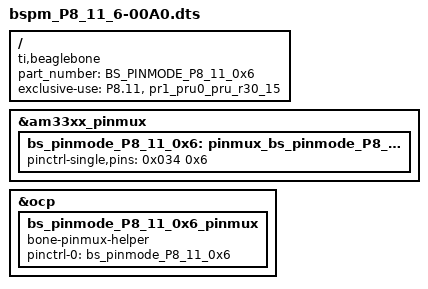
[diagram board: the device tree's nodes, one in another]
/*
 * This is a template-generated file from BoneScript
 */

/dts-v1/;
/plugin/;

/{
    compatible = "ti,beaglebone", "ti,beaglebone-black", "ti,beaglebone-green";
    part_number = "BS_PINMODE_P8_11_0x6";

    exclusive-use =
        "P8.11",
        "pr1_pru0_pru_r30_15";

    fragment@0 {
        target = <&am33xx_pinmux>;
        __overlay__ {
            bs_pinmode_P8_11_0x6: pinmux_bs_pinmode_P8_11_0x6 {
                pinctrl-single,pins = <0x034 0x6>;
            };
        };
    };

    fragment@1 {
        target = <&ocp>;
        __overlay__ {
            bs_pinmode_P8_11_0x6_pinmux {
                compatible = "bone-pinmux-helper";
                status = "okay";
                pinctrl-names = "default";
                pinctrl-0 = <&bs_pinmode_P8_11_0x6>;
            };
        };
    };
};

